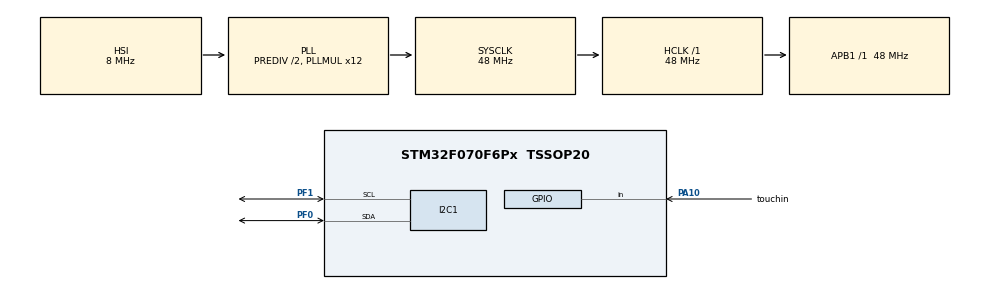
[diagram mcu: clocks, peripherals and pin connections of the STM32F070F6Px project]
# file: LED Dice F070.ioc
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I2C1.Timing=0x20303E5D
Mcu.Family=STM32F0
Mcu.Name=STM32F070F6Px
Mcu.Package=TSSOP20
PA10.GPIO_Label=touchin
PA10.Signal=GPIO_Input
PA13.Mode=Serial_Wire
PA13.Signal=SYS_SWDIO
PA14.Mode=Serial_Wire
PA14.Signal=SYS_SWCLK
PF0-OSC_IN.Mode=I2C
PF0-OSC_IN.Signal=I2C1_SDA
PF1-OSC_OUT.Mode=I2C
PF1-OSC_OUT.Signal=I2C1_SCL
ProjectManager.HeapSize=0x200
ProjectManager.StackSize=0x400
ProjectManager.TargetToolchain=STM32CubeIDE
RCC.AHBFreq_Value=48000000
RCC.APB1Freq_Value=48000000
RCC.APB1TimFreq_Value=48000000
RCC.HCLKFreq_Value=48000000
RCC.I2c1ClockSelection=RCC_I2C1CLKSOURCE_SYSCLK
RCC.PLLDivider=RCC_PREDIV_DIV2
RCC.PLLMUL=RCC_PLL_MUL12
RCC.SYSCLKFreq_VALUE=48000000
RCC.SYSCLKSource=RCC_SYSCLKSOURCE_PLLCLK
board=custom

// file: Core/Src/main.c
/* USER CODE BEGIN Header */
/**
  ******************************************************************************
  * @file           : main.c
  * @brief          : Main program body
  ******************************************************************************
  * @attention
  *
  * Copyright (c) 2024 STMicroelectronics.
  * All rights reserved.
  *
  * This software is licensed under terms that can be found in the LICENSE file
  * in the root directory of this software component.
  * If no LICENSE file comes with this software, it is provided AS-IS.
  *
  ******************************************************************************
  */
/* USER CODE END Header */
#include "main.h"

I2C_HandleTypeDef hi2c1;

/* USER CODE BEGIN PV */
static const uint8_t PCA9535Addr = 0x21 << 1; // Use 8-bit address
static const uint8_t confPort0	 = 0x06;
//static const uint8_t confPort1	 = 0x07;
static const uint8_t writePort0	 = 0x02;
//static const uint8_t writePort1	 = 0x03;

uint8_t i2cBuf[3];
uint8_t j=0;

static const uint8_t num1Arr[36] = {1,2,3,4,5,6,1,1,1,1,1,2,3,4,5,6,2,2,2,2,3,4,5,6,3,3,3,4,5,6,4,4,5,6,5,6};
static const uint8_t num2Arr[36] = {1,1,1,1,1,1,2,3,4,5,6,2,2,2,2,2,3,4,5,6,3,3,3,3,4,5,6,4,4,4,5,6,5,5,6,6};

/* USER CODE END PV */

void SystemClock_Config(void);
static void MX_GPIO_Init(void);
static void MX_I2C1_Init(void);
/* USER CODE BEGIN PFP */

void initPCA9535(void);
void dispPCA9535(uint8_t, uint8_t);
void dispNum(uint8_t);

/* USER CODE END PFP */

int main(void)
{

  /* MCU Configuration--------------------------------------------------------*/

  /* Reset of all peripherals, Initializes the Flash interface and the Systick. */
  HAL_Init();

  /* Configure the system clock */
  SystemClock_Config();

  /* Initialize all configured peripherals */
  MX_GPIO_Init();
  MX_I2C1_Init();
  /* USER CODE BEGIN 2 */

  HAL_Delay(100);

  initPCA9535();

  /* USER CODE END 2 */

  /* Infinite loop */
  /* USER CODE BEGIN WHILE */
  while (1)
  {

//	  for(int j=1;j<37;j++)
//	  {
//		  dispNum(j);
//		  HAL_Delay(1000);
//		  while(!HAL_GPIO_ReadPin(touchin_GPIO_Port, touchin_Pin));
//	  }

	  while(HAL_GPIO_ReadPin(touchin_GPIO_Port, touchin_Pin))
	  {
		  dispNum(j++);
		  if (j>35)
		  {
			  j=0;
		  }
		  HAL_Delay(3);
	  }

    /* USER CODE END WHILE */

  }
}

void SystemClock_Config(void)
{
  RCC_OscInitTypeDef RCC_OscInitStruct = {0};
  RCC_ClkInitTypeDef RCC_ClkInitStruct = {0};
  RCC_PeriphCLKInitTypeDef PeriphClkInit = {0};

  /** Initializes the RCC Oscillators according to the specified parameters
  * in the RCC_OscInitTypeDef structure.
  */
  RCC_OscInitStruct.OscillatorType = RCC_OSCILLATORTYPE_HSI;
  RCC_OscInitStruct.HSIState = RCC_HSI_ON;
  RCC_OscInitStruct.HSICalibrationValue = RCC_HSICALIBRATION_DEFAULT;
  RCC_OscInitStruct.PLL.PLLState = RCC_PLL_ON;
  RCC_OscInitStruct.PLL.PLLSource = RCC_PLLSOURCE_HSI;
  RCC_OscInitStruct.PLL.PLLMUL = RCC_PLL_MUL12;
  RCC_OscInitStruct.PLL.PREDIV = RCC_PREDIV_DIV2;
  if (HAL_RCC_OscConfig(&RCC_OscInitStruct) != HAL_OK)
  {
    Error_Handler();
  }

  /** Initializes the CPU, AHB and APB buses clocks
  */
  RCC_ClkInitStruct.ClockType = RCC_CLOCKTYPE_HCLK|RCC_CLOCKTYPE_SYSCLK
                              |RCC_CLOCKTYPE_PCLK1;
  RCC_ClkInitStruct.SYSCLKSource = RCC_SYSCLKSOURCE_PLLCLK;
  RCC_ClkInitStruct.AHBCLKDivider = RCC_SYSCLK_DIV1;
  RCC_ClkInitStruct.APB1CLKDivider = RCC_HCLK_DIV1;

  if (HAL_RCC_ClockConfig(&RCC_ClkInitStruct, FLASH_LATENCY_1) != HAL_OK)
  {
    Error_Handler();
  }
  PeriphClkInit.PeriphClockSelection = RCC_PERIPHCLK_I2C1;
  PeriphClkInit.I2c1ClockSelection = RCC_I2C1CLKSOURCE_SYSCLK;
  if (HAL_RCCEx_PeriphCLKConfig(&PeriphClkInit) != HAL_OK)
  {
    Error_Handler();
  }
}

static void MX_I2C1_Init(void)
{

  hi2c1.Instance = I2C1;
  hi2c1.Init.Timing = 0x20303E5D;
  hi2c1.Init.OwnAddress1 = 0;
  hi2c1.Init.AddressingMode = I2C_ADDRESSINGMODE_7BIT;
  hi2c1.Init.DualAddressMode = I2C_DUALADDRESS_DISABLE;
  hi2c1.Init.OwnAddress2 = 0;
  hi2c1.Init.OwnAddress2Masks = I2C_OA2_NOMASK;
  hi2c1.Init.GeneralCallMode = I2C_GENERALCALL_DISABLE;
  hi2c1.Init.NoStretchMode = I2C_NOSTRETCH_DISABLE;
  if (HAL_I2C_Init(&hi2c1) != HAL_OK)
  {
    Error_Handler();
  }

  /** Configure Analogue filter
  */
  if (HAL_I2CEx_ConfigAnalogFilter(&hi2c1, I2C_ANALOGFILTER_ENABLE) != HAL_OK)
  {
    Error_Handler();
  }

  /** Configure Digital filter
  */
  if (HAL_I2CEx_ConfigDigitalFilter(&hi2c1, 0) != HAL_OK)
  {
    Error_Handler();
  }

}

static void MX_GPIO_Init(void)
{
  GPIO_InitTypeDef GPIO_InitStruct = {0};

  /* GPIO Ports Clock Enable */
  __HAL_RCC_GPIOF_CLK_ENABLE();
  __HAL_RCC_GPIOA_CLK_ENABLE();

  /*Configure GPIO pin : touchin_Pin */
  GPIO_InitStruct.Pin = touchin_Pin;
  GPIO_InitStruct.Mode = GPIO_MODE_INPUT;
  GPIO_InitStruct.Pull = GPIO_NOPULL;
  HAL_GPIO_Init(touchin_GPIO_Port, &GPIO_InitStruct);

}

/* USER CODE BEGIN 4 */

void initPCA9535()
{
	i2cBuf[0] = confPort0;
	i2cBuf[1] = 0;
	i2cBuf[2] = 0;

	HAL_I2C_Master_Transmit(&hi2c1, PCA9535Addr, i2cBuf, 3, 100);
}

void dispPCA9535(uint8_t diceNum1, uint8_t diceNum2)
{
	i2cBuf[0] = writePort0;

	switch (diceNum1)
	{
	case 1: 	{ i2cBuf[1] = 0B00001000; break;}
	case 2: 	{ i2cBuf[1] = 0B00010001; break;}
	case 3: 	{ i2cBuf[1] = 0B00011001; break;}
	case 4: 	{ i2cBuf[1] = 0B01010101; break;}
	case 5: 	{ i2cBuf[1] = 0B01011101; break;}
	case 6: 	{ i2cBuf[1] = 0B01110111; break;}
	default: 	{ i2cBuf[1] = 0B11111111; break;}
	}

	switch (diceNum2)
	{
	case 1: 	{ i2cBuf[2] = 0B00001000; break;}
	case 2: 	{ i2cBuf[2] = 0B00010001; break;}
	case 3: 	{ i2cBuf[2] = 0B00011001; break;}
	case 4: 	{ i2cBuf[2] = 0B01010101; break;}
	case 5: 	{ i2cBuf[2] = 0B01011101; break;}
	case 6: 	{ i2cBuf[2] = 0B01110111; break;}
	default: 	{ i2cBuf[2] = 0B11111111; break;}
	}

	HAL_I2C_Master_Transmit(&hi2c1, PCA9535Addr, i2cBuf, 3, 100);
}

void dispNum(uint8_t num)
{
	dispPCA9535(num1Arr[num], num2Arr[num]);
}

/* USER CODE END 4 */

void Error_Handler(void)
{
  __disable_irq();
  while (1)
  {
  }
}
